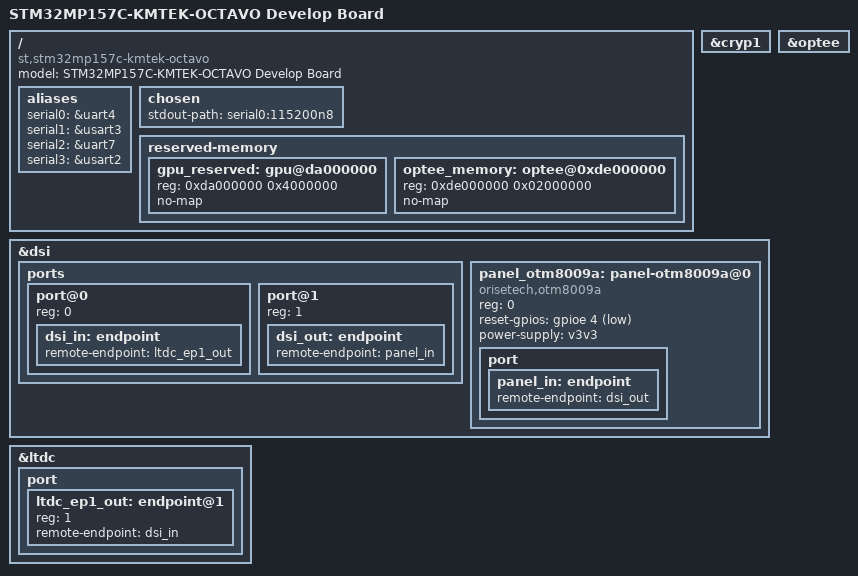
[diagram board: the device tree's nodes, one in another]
// SPDX-License-Identifier: (GPL-2.0+ OR BSD-3-Clause)
/*
 * Copyright (C) STMicroelectronics 2019 - All Rights Reserved
 * Author: Alexandre Torgue <alexandre.torgue@st.com> for STMicroelectronics.
 */

/dts-v1/;

#include "stm32mp157.dtsi"
#include "stm32mp15xc.dtsi"
#include "stm32mp15-pinctrl.dtsi"
#include "stm32mp15xxac-pinctrl.dtsi"
#include "stm32mp157c-kmtek-octavo.dtsi"
#include <dt-bindings/rtc/rtc-stm32.h>

/ {
	model = "STM32MP157C-KMTEK-OCTAVO Develop Board";
	compatible = "st,stm32mp157c-kmtek-octavo", "st,stm32mp157";

	aliases {
		serial0 = &uart4;
		serial1 = &usart3;
		serial2 = &uart7;
		serial3 = &usart2;
	};

	chosen {
		stdout-path = "serial0:115200n8";
	};

	reserved-memory {
		gpu_reserved: gpu@da000000 {
			reg = <0xda000000 0x4000000>;
			no-map;
		};

		optee_memory: optee@0xde000000 {
			reg = <0xde000000 0x02000000>;
			no-map;
		};
	};

};

&cryp1 {
	status="okay";
};

&dsi {
	#address-cells = <1>;
	#size-cells = <0>;
	status = "okay";

	ports {
		#address-cells = <1>;
		#size-cells = <0>;

		port@0 {
			reg = <0>;
			dsi_in: endpoint {
				remote-endpoint = <&ltdc_ep1_out>;
			};
		};

		port@1 {
			reg = <1>;
			dsi_out: endpoint {
				remote-endpoint = <&panel_in>;
			};
		};
	};

	panel_otm8009a: panel-otm8009a@0 {
		compatible = "orisetech,otm8009a";
		reg = <0>;
		reset-gpios = <&gpioe 4 GPIO_ACTIVE_LOW>;
		power-supply = <&v3v3>;
		status = "okay";

		port {
			panel_in: endpoint {
				remote-endpoint = <&dsi_out>;
			};
		};
	};
};

&ltdc {
	status = "okay";

	port {
		#address-cells = <1>;
		#size-cells = <0>;

		ltdc_ep1_out: endpoint@1 {
			reg = <1>;
			remote-endpoint = <&dsi_in>;
		};
	};
};


&optee_memory {
	status = "okay";
};

&optee {
	status = "okay";
};
